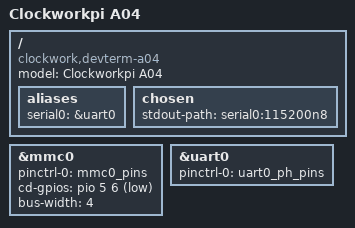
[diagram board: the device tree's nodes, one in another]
// SPDX-License-Identifier: (GPL-2.0+ or MIT)
/*
 * Copyright (C) 2018 Amarula Solutions
 * Author: Jagan Teki <jagan@amarulasolutions.com>
 */
/dts-v1/;
#include "sun50i-h6.dtsi"
#include <dt-bindings/gpio/gpio.h>
/ {
	model = "Clockworkpi A04";
	compatible = "clockwork,devterm-a04", "allwinner,sun50i-h6";
	aliases {
		serial0 = &uart0;
	};
	chosen {
		stdout-path = "serial0:115200n8";
	};
};
&mmc0 {
	pinctrl-names = "default";
	pinctrl-0 = <&mmc0_pins>;
	cd-gpios = <&pio 5 6 GPIO_ACTIVE_LOW>;
	bus-width = <4>;
	status = "okay";
};
&uart0 {
	pinctrl-names = "default";
	pinctrl-0 = <&uart0_ph_pins>;
	status = "okay";
};
